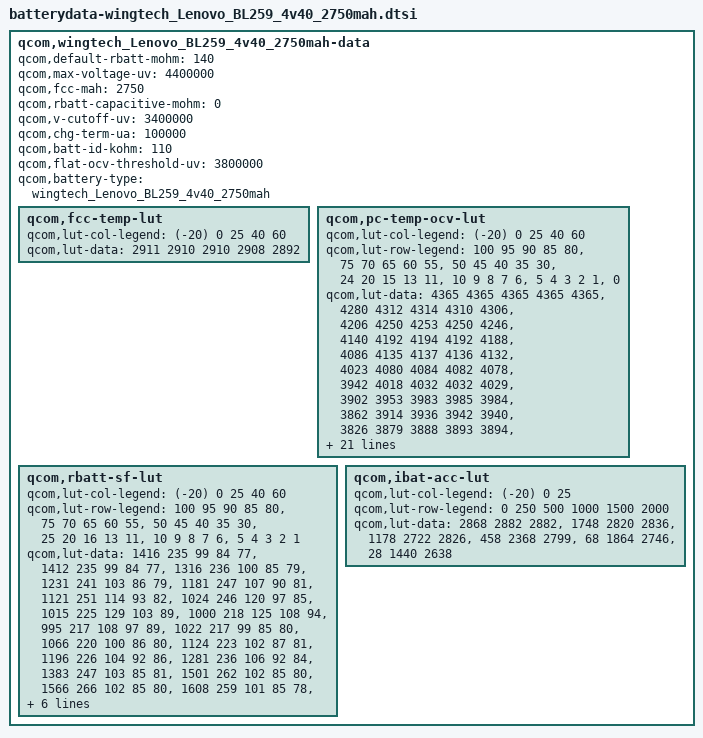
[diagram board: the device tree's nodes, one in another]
/* Copyright (c) 2014, The Linux Foundation. All rights reserved.
 *
 * This program is free software; you can redistribute it and/or modify
 * it under the terms of the GNU General Public License version 2 and
 * only version 2 as published by the Free Software Foundation.
 *
 * This program is distributed in the hope that it will be useful,
 * but WITHOUT ANY WARRANTY; without even the implied warranty of
 * MERCHANTABILITY or FITNESS FOR A PARTICULAR PURPOSE.  See the
 * GNU General Public License for more details.
 */


qcom,wingtech_Lenovo_BL259_4v40_2750mah-data {
	qcom,default-rbatt-mohm = <140>;
	qcom,max-voltage-uv = <4400000>;
	qcom,fcc-mah = <2750>;
	qcom,rbatt-capacitive-mohm = <0>;
	qcom,v-cutoff-uv = <3400000>;
	qcom,chg-term-ua = <100000>;
	qcom,batt-id-kohm = <110>;
	qcom,flat-ocv-threshold-uv = <3800000>;
	qcom,battery-type = "wingtech_Lenovo_BL259_4v40_2750mah";

	qcom,fcc-temp-lut {
		qcom,lut-col-legend = <(-20) 0 25 40 60>;
		qcom,lut-data = <2911 2910 2910 2908 2892>;
	};

	qcom,pc-temp-ocv-lut {
			qcom,lut-col-legend = <(-20) 0 25 40 60>;
		  qcom,lut-row-legend = <100 95 90 85 80>,
					<75 70 65 60 55>,
					<50 45 40 35 30>,
					<24 20 15 13 11>, 
					<10 9 8 7 6>,
					<5 4 3 2 1>,
					<0>;
		  qcom,lut-data = <4365 4365 4365 4365 4365>, //100
				<4280 4312 4314 4310 4306>,   //95
				<4206 4250 4253 4250 4246>,   //90
				<4140 4192 4194 4192 4188>,   //85
				<4086 4135 4137 4136 4132>,   //80
				<4023 4080 4084 4082 4078>,   //75
				<3942 4018 4032 4032 4029>,   //70   
				<3902 3953 3983 3985 3984>,   //65   
				<3862 3914 3936 3942 3940>,   //60   
				<3826 3879 3888 3893 3894>,   //55   
				<3804 3847 3852 3854 3854>,   //50   
				<3788 3820 3826 3828 3826>,   //45   
				<3774 3799 3806 3807 3806>,   //40   
				<3762 3782 3789 3790 3789>,   //35   
				<3749 3770 3779 3779 3770>,   //30   
				<3736 3758 3769 3769 3750>,   //25  
				<3721 3743 3740 3730 3720>,   //20   
				<3707 3712 3712 3712 3700>,   //16  ---> 15  
				<3693 3707 3702 3693 3680>,   //13   
				<3680 3698 3692 3684 3672>,   //11   
				<3673 3696 3690 3682 3672>,   //10   
				<3664 3692 3688 3682 3670>,   //9    
				<3654 3690 3687 3680 3669>,   //8    
				<3641 3686 3685 3678 3666>,   //7    
				<3624 3682 3680 3672 3657>,   //6    
				<3602 3668 3663 3649 3631>,   //5    
				<3572 3629 3618 3606 3586>,   //4    
				<3525 3570 3558 3545 3526>,   //3    
				<3458 3490 3478 3468 3447>,   //2    
				<3340 3368 3352 3336 3324>,   //1
				<3000 3000 3000 3000 3000>;   //0
	};

	qcom,rbatt-sf-lut {
		qcom,lut-col-legend = <(-20) 0 25 40 60>;
		qcom,lut-row-legend = <100 95 90 85 80>,
					<75 70 65 60 55>,
					<50 45 40 35 30>,
					<25 20 16 13 11>,
					<10 9 8 7 6>,
					<5 4 3 2 1>;
		qcom,lut-data = <1416 235 99 84 77>,
				<1412 235 99 84 77>,
				<1316 236 100 85 79>,
				<1231 241 103 86 79>,
				<1181 247 107 90 81>,
				<1121 251 114 93 82>,
				<1024 246 120 97 85>,
				<1015 225 129 103 89>,
				<1000 218 125 108 94>,
				<995 217 108 97 89>,
				<1022 217 99 85 80>,
				<1066 220 100 86 80>,
				<1124 223 102 87 81>,
				<1196 226 104 92 86>,
				<1281 236 106 92 84>,
				<1383 247 103 85 81>,
				<1501 262 102 85 80>,
				<1566 266 102 85 80>,
				<1608 259 101 85 78>,
				<1714 275 100 84 78>,
				<1776 286 102 86 80>,
				<1847 298 104 88 81>,
				<1921 319 107 91 85>,
				<2018 342 112 94 90>,
				<2140 375 115 100 90>,
				<2553 403 114 92 85>,
				<3325 431 109 91 83>,
				<4898 530 115 93 86>,
				<8080 734 125 100 93>,
				<16159 1420 163 144 113>;
	};

	qcom,ibat-acc-lut {
		qcom,lut-col-legend = <(-20) 0 25>;
		qcom,lut-row-legend = <0 250 500 1000 1500 2000>;
		qcom,lut-data = 
								<2868 2882 2882>,
								<1748 2820 2836>,
								<1178 2722 2826>,
								<458  2368 2799>,
								<68   1864 2746>,
								<28   1440 2638>;
							
	};
};
